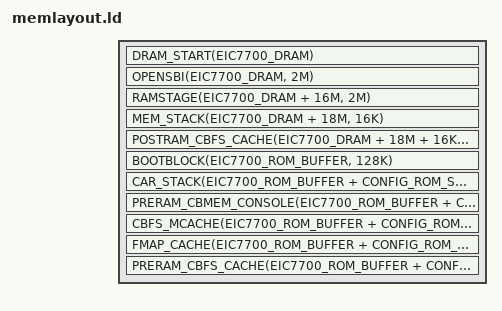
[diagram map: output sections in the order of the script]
/* SPDX-License-Identifier: GPL-2.0-only */
#include <memlayout.h>
#include <arch/header.ld>
#include <soc/addressmap.h>

SECTIONS
{
	DRAM_START(EIC7700_DRAM)
	OPENSBI(EIC7700_DRAM, 2M)
	RAMSTAGE(EIC7700_DRAM + 16M, 2M)
	MEM_STACK(EIC7700_DRAM + 18M, 16K)
	POSTRAM_CBFS_CACHE(EIC7700_DRAM + 18M + 16K, 14M - 16K)

	/* SCPU supplies initialized DRAM. No cache-as-RAM setup is needed. */
	BOOTBLOCK(EIC7700_ROM_BUFFER, 128K)
	CAR_STACK(EIC7700_ROM_BUFFER + CONFIG_ROM_SIZE, 16K)
	PRERAM_CBMEM_CONSOLE(EIC7700_ROM_BUFFER + CONFIG_ROM_SIZE + 16K, 8K)
	CBFS_MCACHE(EIC7700_ROM_BUFFER + CONFIG_ROM_SIZE + 24K, 8K)
	FMAP_CACHE(EIC7700_ROM_BUFFER + CONFIG_ROM_SIZE + 32K, 4K)
	PRERAM_CBFS_CACHE(EIC7700_ROM_BUFFER + CONFIG_ROM_SIZE + 36K, 128K)
}
